AUTOSAR XML (schema 00048)
package /AUTOLIV/SoftwareComponents/ATM
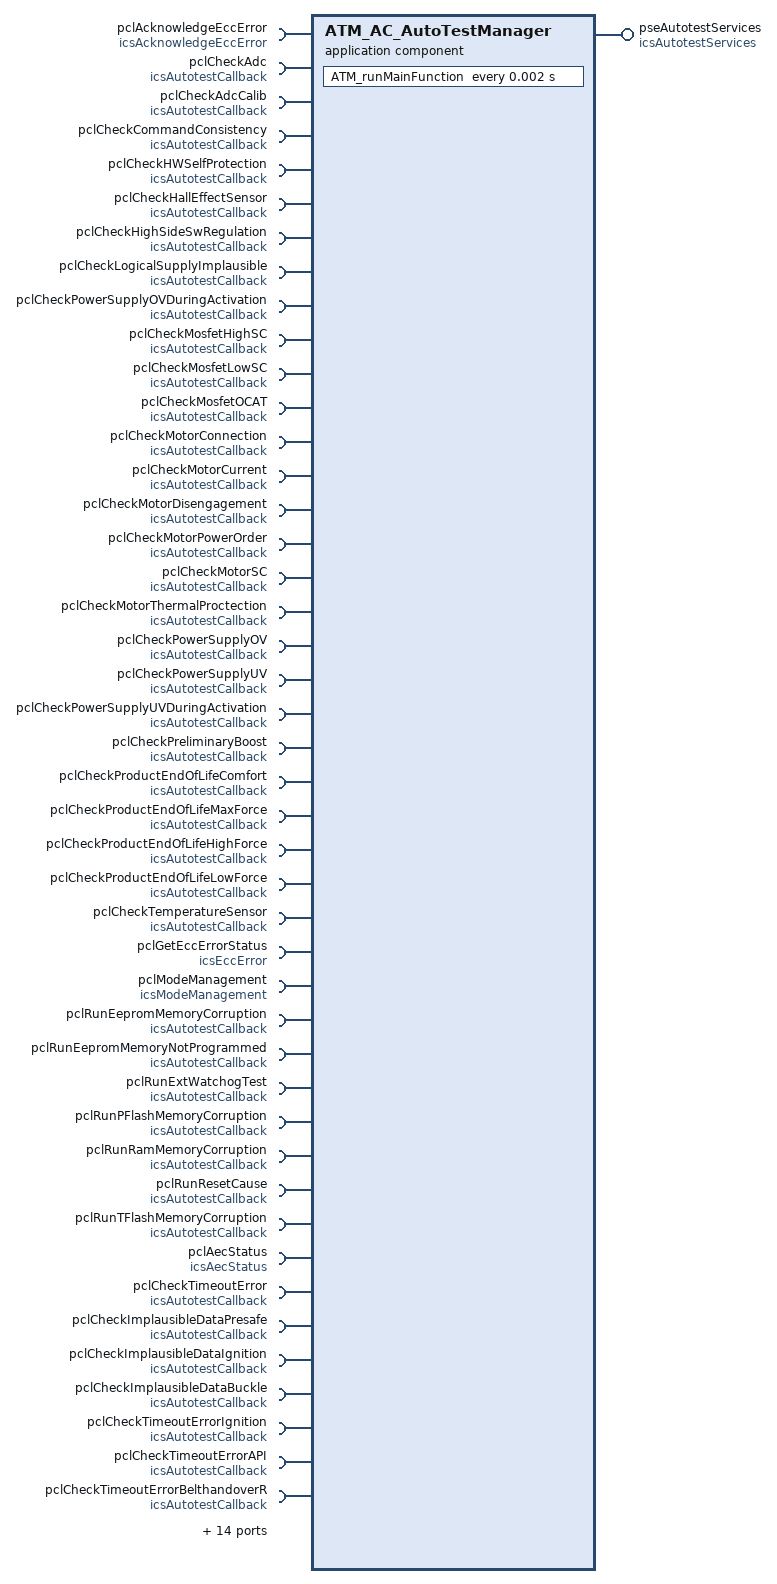
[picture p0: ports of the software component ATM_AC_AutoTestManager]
  application sw component type ATM_AC_AutoTestManager
    36 x require port:
      pclAcknowledgeEccError: client-com-spec=AcknowledgeEccError, required-interface=icsAcknowledgeEccError  # Port to acknowledge ECC error status
      pclCheckAdc: client-com-spec=AutotestCallback, required-interface=icsAutotestCallback
      pclCheckAdcCalib: client-com-spec=AutotestCallback, required-interface=icsAutotestCallback
      pclCheckCommandConsistency: client-com-spec=AutotestCallback, required-interface=icsAutotestCallback
      pclCheckHWSelfProtection: client-com-spec=AutotestCallback, required-interface=icsAutotestCallback
      pclCheckHallEffectSensor: client-com-spec=AutotestCallback, required-interface=icsAutotestCallback
      pclCheckHighSideSwRegulation: client-com-spec=AutotestCallback, required-interface=icsAutotestCallback
      pclCheckLogicalSupplyImplausible: client-com-spec=AutotestCallback, required-interface=icsAutotestCallback
      pclCheckPowerSupplyOVDuringActivation: client-com-spec=AutotestCallback, required-interface=icsAutotestCallback
      pclCheckMosfetHighSC: client-com-spec=AutotestCallback, required-interface=icsAutotestCallback
      pclCheckMosfetLowSC: client-com-spec=AutotestCallback, required-interface=icsAutotestCallback
      pclCheckMosfetOCAT: client-com-spec=AutotestCallback, required-interface=icsAutotestCallback
      pclCheckMotorConnection: client-com-spec=AutotestCallback, required-interface=icsAutotestCallback
      pclCheckMotorCurrent: client-com-spec=AutotestCallback, required-interface=icsAutotestCallback
      pclCheckMotorDisengagement: client-com-spec=AutotestCallback, required-interface=icsAutotestCallback
      pclCheckMotorPowerOrder: client-com-spec=AutotestCallback, required-interface=icsAutotestCallback
      pclCheckMotorSC: client-com-spec=AutotestCallback, required-interface=icsAutotestCallback
      pclCheckMotorThermalProctection: client-com-spec=AutotestCallback, required-interface=icsAutotestCallback
      pclCheckPowerSupplyOV: client-com-spec=AutotestCallback, required-interface=icsAutotestCallback
      pclCheckPowerSupplyUV: client-com-spec=AutotestCallback, required-interface=icsAutotestCallback
      pclCheckPowerSupplyUVDuringActivation: client-com-spec=AutotestCallback, required-interface=icsAutotestCallback
      pclCheckPreliminaryBoost: client-com-spec=AutotestCallback, required-interface=icsAutotestCallback
      pclCheckProductEndOfLifeComfort: client-com-spec=AutotestCallback, required-interface=icsAutotestCallback
      pclCheckProductEndOfLifeMaxForce: client-com-spec=AutotestCallback, required-interface=icsAutotestCallback
      pclCheckProductEndOfLifeHighForce: client-com-spec=AutotestCallback, required-interface=icsAutotestCallback
      pclCheckProductEndOfLifeLowForce: client-com-spec=AutotestCallback, required-interface=icsAutotestCallback
      pclCheckTemperatureSensor: client-com-spec=AutotestCallback, required-interface=icsAutotestCallback
      pclGetEccErrorStatus: client-com-spec=GetEccError, required-interface=icsEccError  # Port to get ECC error status
      pclModeManagement: client-com-spec=CheckModeStatus, required-interface=icsModeManagement
      pclRunEepromMemoryCorruption: client-com-spec=AutotestCallback, required-interface=icsAutotestCallback
      pclRunEepromMemoryNotProgrammed: client-com-spec=AutotestCallback, required-interface=icsAutotestCallback
      pclRunExtWatchogTest: client-com-spec=AutotestCallback, required-interface=icsAutotestCallback
      pclRunPFlashMemoryCorruption: client-com-spec=AutotestCallback, required-interface=icsAutotestCallback
      pclRunRamMemoryCorruption: client-com-spec=AutotestCallback, required-interface=icsAutotestCallback
      pclRunResetCause: client-com-spec=AutotestCallback, required-interface=icsAutotestCallback
      pclRunTFlashMemoryCorruption: client-com-spec=AutotestCallback, required-interface=icsAutotestCallback
    provide port pseAutotestServices: provided-com-specs=[{operation=GetLastCriticalAutotestID, queue-length=1}, {operation=GetTestResult, queue-length=1}], provided-interface=icsAutotestServices
    22 x require port:
      pclAecStatus: required-interface=icsAecStatus
        required-com-specs:
          SetAecEvent
          GetNumberOfImplementedAec
          GetAecStatus
          GetAecQualificationCount
          GetAecNvpBlockRecordingStatus
          GetAecGroupsStatus
          GetAecDeskillThrs
      pclCheckTimeoutError: client-com-spec=AutotestCallback, required-interface=icsAutotestCallback
      pclCheckImplausibleDataPresafe: client-com-spec=AutotestCallback, required-interface=icsAutotestCallback
      pclCheckImplausibleDataIgnition: client-com-spec=AutotestCallback, required-interface=icsAutotestCallback
      pclCheckImplausibleDataBuckle: client-com-spec=AutotestCallback, required-interface=icsAutotestCallback
      pclCheckTimeoutErrorIgnition: client-com-spec=AutotestCallback, required-interface=icsAutotestCallback
      pclCheckTimeoutErrorAPI: client-com-spec=AutotestCallback, required-interface=icsAutotestCallback
      pclCheckTimeoutErrorBelthandoverR: client-com-spec=AutotestCallback, required-interface=icsAutotestCallback
      pclCheckTimeoutErrorBelthandoverL: client-com-spec=AutotestCallback, required-interface=icsAutotestCallback
      pclCheckTimeoutErrorPowertrain: client-com-spec=AutotestCallback, required-interface=icsAutotestCallback
      pclCheckImplausibleDataPowertrainDrv: client-com-spec=AutotestCallback, required-interface=icsAutotestCallback
      pclCheckImplausibleDataORC: client-com-spec=AutotestCallback, required-interface=icsAutotestCallback
      pclCheckSteeringConfiguration: client-com-spec=AutotestCallback, required-interface=icsAutotestCallback
      pclCheckSystemOV: client-com-spec=AutotestCallback, required-interface=icsAutotestCallback
      pclCheckSystemUV: client-com-spec=AutotestCallback, required-interface=icsAutotestCallback
      pclCheckImplausibleDataPowertrainRdy: client-com-spec=AutotestCallback, required-interface=icsAutotestCallback
      pclCheckTimeoutErrorOdoSpeedometer: client-com-spec=AutotestCallback, required-interface=icsAutotestCallback
      pclCheckVariantCodining: client-com-spec=AutotestCallback, required-interface=icsAutotestCallback
      pclCheckTimeoutErrorBuckle: client-com-spec=AutotestCallback, required-interface=icsAutotestCallback
      pclCheckImplausibleDataAPI: client-com-spec=AutotestCallback, required-interface=icsAutotestCallback
      pclCheckTimeoutErrorBeltAdj: client-com-spec=AutotestCallback, required-interface=icsAutotestCallback
      pcs_ServiceAutotest: client-com-spec=GetTestResult, required-interface=ics_ServiceAutotest
    behavior ATM_IB_AutoTestManager: data-type-mapping=DataTypeMappingSet_PP4G
      operation invoked event ATM_evGetLastCriticalAutotestId: start-on-event=ATM_runGetLastCriticalAutotestId, operation=pseAutotestServices.GetLastCriticalAutotestID
      operation invoked event ATM_evGetTestResult: start-on-event=ATM_runGetTestResult, operation=pseAutotestServices.GetTestResult
      timing event ATM_evMainFunction: start-on-event=ATM_runMainFunction, period=0.002
      init event ATM_InitEvent: start-on-event=ATM_Init
      4 x runnable:
        ATM_Init
          sync call scp_AutotestCallback: operation=pclRunExtWatchogTest.AutotestCallback
        ATM_runGetLastCriticalAutotestId: can-be-invoked-concurrently=true
        ATM_runGetTestResult: can-be-invoked-concurrently=true
        ATM_runMainFunction
          60 x sync call:
            SSCP_pclAcknowledgeEccError_AcknowledgeEccError: operation=pclAcknowledgeEccError.AcknowledgeEccError
            SSCP_pclGetEccErrorStatus_GetEccError: operation=pclGetEccErrorStatus.GetEccError
            SSCP_pclModeManagement_CheckModeStatus: operation=pclModeManagement.CheckModeStatus
            scp_AutotestCallback: operation=pclCheckAdc.AutotestCallback
            scp_AutotestCallback1: operation=pclRunResetCause.AutotestCallback
            scp_AutotestCallback10: operation=pclCheckPreliminaryBoost.AutotestCallback
            scp_AutotestCallback12: operation=pclCheckMotorCurrent.AutotestCallback
            scp_AutotestCallback13: operation=pclCheckMotorDisengagement.AutotestCallback
            scp_AutotestCallback14: operation=pclCheckMotorThermalProctection.AutotestCallback
            scp_AutotestCallback15: operation=pclCheckMotorSC.AutotestCallback
            scp_AutotestCallback16: operation=pclCheckMotorPowerOrder.AutotestCallback
            scp_AutotestCallback18: operation=pclCheckMotorConnection.AutotestCallback
            scp_AutotestCallback19: operation=pclRunPFlashMemoryCorruption.AutotestCallback
            scp_AutotestCallback2: operation=pclRunEepromMemoryCorruption.AutotestCallback
            scp_AutotestCallback20: operation=pclRunRamMemoryCorruption.AutotestCallback
            scp_AutotestCallback21: operation=pclRunTFlashMemoryCorruption.AutotestCallback
            scp_AutotestCallback22: operation=pclCheckHallEffectSensor.AutotestCallback
            scp_AutotestCallback23: operation=pclCheckTemperatureSensor.AutotestCallback
            scp_AutotestCallback24: operation=pclCheckPowerSupplyUV.AutotestCallback
            scp_AutotestCallback25: operation=pclCheckPowerSupplyUVDuringActivation.AutotestCallback
            scp_AutotestCallback26: operation=pclCheckPowerSupplyOVDuringActivation.AutotestCallback
            scp_AutotestCallback28: operation=pclCheckLogicalSupplyImplausible.AutotestCallback
            scp_AutotestCallback29: operation=pclCheckProductEndOfLifeLowForce.AutotestCallback
            scp_AutotestCallback3: operation=pclRunEepromMemoryNotProgrammed.AutotestCallback
            scp_AutotestCallback30: operation=pclCheckProductEndOfLifeHighForce.AutotestCallback
            scp_AutotestCallback31: operation=pclCheckProductEndOfLifeComfort.AutotestCallback
            scp_AutotestCallback32: operation=pclCheckProductEndOfLifeMaxForce.AutotestCallback
            scp_AutotestCallback33: operation=pclCheckPowerSupplyOV.AutotestCallback
            scp_AutotestCallback34: operation=pclCheckAdcCalib.AutotestCallback
            scp_AutotestCallback35: operation=pclRunExtWatchogTest.AutotestCallback
            scp_AutotestCallback4: operation=pclCheckHighSideSwRegulation.AutotestCallback
            scp_AutotestCallback5: operation=pclCheckCommandConsistency.AutotestCallback
            scp_AutotestCallback6: operation=pclCheckMosfetHighSC.AutotestCallback
            scp_AutotestCallback7: operation=pclCheckMosfetLowSC.AutotestCallback
            scp_AutotestCallback8: operation=pclCheckHWSelfProtection.AutotestCallback
            scp_AutotestCallback9: operation=pclCheckMosfetOCAT.AutotestCallback
            SC_pclAecStatus_SetAecEvent: operation=pclAecStatus.SetAecEvent
            SC_pclAecStatus_GetAecDeskillThrs: operation=pclAecStatus.GetAecDeskillThrs
            SC_pclAecStatus_GetAecStatus: operation=pclAecStatus.GetAecStatus
            SC_pclCheckTimeoutError_AutotestCallback: operation=pclCheckTimeoutError.AutotestCallback
            SC_pclCheckImplausibleDataPresafe_AutotestCallback: operation=pclCheckImplausibleDataPresafe.AutotestCallback
            SC_pclCheckImplausibleDataBuckle_AutotestCallback: operation=pclCheckImplausibleDataBuckle.AutotestCallback
            SC_pclCheckImplausibleDataIgnition_AutotestCallback: operation=pclCheckImplausibleDataIgnition.AutotestCallback
            SC_pclCheckImplausibleDataORC_AutotestCallback: operation=pclCheckImplausibleDataORC.AutotestCallback
            SC_pclCheckSteeringConfiguration_AutotestCallback: operation=pclCheckSteeringConfiguration.AutotestCallback
            SC_pclCheckSystemOV_AutotestCallback: operation=pclCheckSystemOV.AutotestCallback
            SC_pclCheckSystemUV_AutotestCallback: operation=pclCheckSystemUV.AutotestCallback
            SC_pclCheckTimeoutErrorAPI_AutotestCallback: operation=pclCheckTimeoutErrorAPI.AutotestCallback
            SC_pclCheckTimeoutErrorBelthandoverL_AutotestCallback: operation=pclCheckTimeoutErrorBelthandoverL.AutotestCallback
            SC_pclCheckTimeoutErrorBelthandoverR_AutotestCallback: operation=pclCheckTimeoutErrorBelthandoverR.AutotestCallback
            SC_pclCheckTimeoutErrorIgnition_AutotestCallback: operation=pclCheckTimeoutErrorIgnition.AutotestCallback
            SC_pclCheckImplausibleDataPowertrainDrv_AutotestCallback: operation=pclCheckImplausibleDataPowertrainDrv.AutotestCallback
            SC_pclCheckImplausibleDataPowertrainRdy_AutotestCallback: operation=pclCheckImplausibleDataPowertrainRdy.AutotestCallback
            SC_pclCheckImplausibleDataAPI_AutotestCallback: operation=pclCheckImplausibleDataAPI.AutotestCallback
            SC_pclCheckTimeoutErrorBuckle_AutotestCallback: operation=pclCheckTimeoutErrorBuckle.AutotestCallback
            SC_pclCheckTimeoutErrorOdoSpeedometer_AutotestCallback: operation=pclCheckTimeoutErrorOdoSpeedometer.AutotestCallback
            SC_pclCheckVariantCodining_AutotestCallback: operation=pclCheckVariantCodining.AutotestCallback
            SC_pclCheckTimeoutErrorPowertrain_AutotestCallback: operation=pclCheckTimeoutErrorPowertrain.AutotestCallback
            SC_pclCheckTimeoutErrorBeltAdj_AutotestCallback: operation=pclCheckTimeoutErrorBeltAdj.AutotestCallback
            SC_pcs_ServiceAutotest_GetTestResult: operation=pcs_ServiceAutotest.GetTestResult
  swc implementation ATM_impAutoTestManager: behavior=ATM_IB_AutoTestManager
    code-descriptors:
      code ATM_Impl_Code: artifact-descriptors=autosar-engineering-object=category=SWSRC
